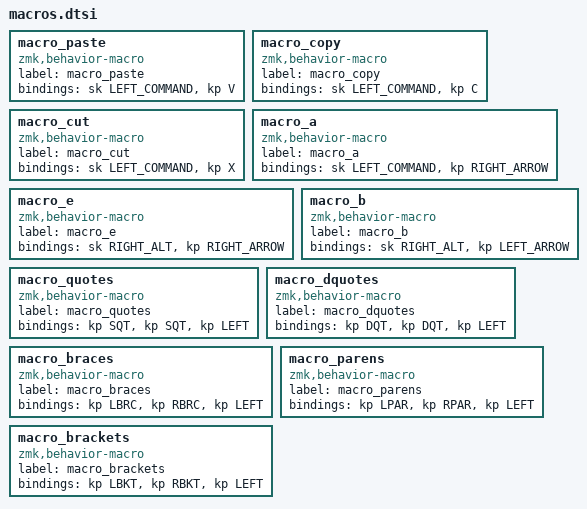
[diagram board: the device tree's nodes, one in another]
macro_paste: macro_paste{
compatible = "zmk,behavior-macro";
label = "macro_paste";
#binding-cells = <0>;
bindings = <&sk LEFT_COMMAND>, <&kp V>;
};
macro_copy: macro_copy{
compatible = "zmk,behavior-macro";
label = "macro_copy";
#binding-cells = <0>;
bindings = <&sk LEFT_COMMAND>, <&kp C>;
};
macro_cut: macro_cut{
compatible = "zmk,behavior-macro";
label = "macro_cut";
#binding-cells = <0>;
bindings = <&sk LEFT_COMMAND>, <&kp X>;
};
macro_a: macro_a{
compatible = "zmk,behavior-macro";
label = "macro_a";
#binding-cells = <0>;
bindings = <&sk LEFT_COMMAND>, <&kp RIGHT_ARROW>;
};
macro_e: macro_e{
compatible = "zmk,behavior-macro";
label = "macro_e";
#binding-cells = <0>;
bindings = <&sk RIGHT_ALT>, <&kp RIGHT_ARROW>;
};
macro_b: macro_b{
compatible = "zmk,behavior-macro";
label = "macro_b";
#binding-cells = <0>;
bindings = <&sk RIGHT_ALT>, <&kp LEFT_ARROW>;
};
macro_quotes: macro_quotes{
compatible = "zmk,behavior-macro";
label = "macro_quotes";
#binding-cells = <0>;
bindings = <&kp SQT>, <&kp SQT>, <&kp LEFT>;
};
macro_dquotes: macro_dquotes{
compatible = "zmk,behavior-macro";
label = "macro_dquotes";
#binding-cells = <0>;
bindings = <&kp DQT>, <&kp DQT>, <&kp LEFT>;
};
macro_braces: macro_braces{
compatible = "zmk,behavior-macro";
label = "macro_braces";
#binding-cells = <0>;
bindings = <&kp LBRC>, <&kp RBRC>, <&kp LEFT>;
};
macro_parens: macro_parens{
compatible = "zmk,behavior-macro";
label = "macro_parens";
#binding-cells = <0>;
bindings = <&kp LPAR>, <&kp RPAR>, <&kp LEFT>;
};
macro_brackets: macro_brackets{
compatible = "zmk,behavior-macro";
label = "macro_brackets";
#binding-cells = <0>;
bindings = <&kp LBKT>, <&kp RBKT>, <&kp LEFT>;
};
